VERSION ""

NS_ :

BS_:

BU_: DBG MASTER MOTOR SENSORS GEO BT

BO_ 95 HB_SENSORS: 1 SENSORS
 SG_ SENSOR_ALIVE : 0|1@1+ (1,0) [0|0] "HB-S" MASTER,MOTOR,GEO,BT

BO_ 96 HB_MOTORS: 1 MOTOR
 SG_ MOTOR_ALIVE : 0|1@1+ (1,0) [0|0] "HB-M" MASTER,SENSORS,GEO,BT

BO_ 97 HB_GEO: 1 GEO
 SG_ GEO_ALIVE : 0|1@1+ (1,0) [0|0] "HB-G" MASTER,SENSORS,MOTOR,BT

BO_ 98 HB_BT: 1 BT
 SG_ BT_ALIVE : 0|1@1+ (1,0) [0|0] "HB-BT" MASTER,SENSORS,MOTOR,GEO

BO_ 99 HB_MASTER: 1 MASTER
 SG_ MASTER_ALIVE : 0|1@1+ (1,0) [0|0] "HB-MT" BT,SENSORS,MOTOR,GEO

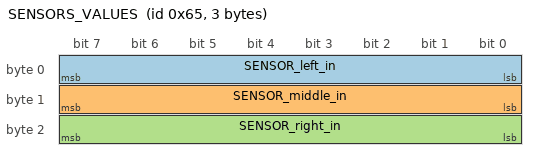
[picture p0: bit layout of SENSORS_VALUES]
BO_ 101 SENSORS_VALUES: 3 SENSORS
 SG_ SENSOR_left_in : 0|8@1+ (1,0) [0|0] "Inches" MASTER
 SG_ SENSOR_middle_in : 8|8@1+ (1,0) [0|0] "Inches" MASTER
 SG_ SENSOR_right_in : 16|8@1+ (1,0) [0|0] "Inches" MASTER

BO_ 203 MASTER_SPEED: 1 MASTER
 SG_ MASTER_Maintain_Speed : 0|8@1+ (1,0) [0|30] "mph" MOTOR

BO_ 204 MASTER_DIRECTION: 1 MASTER
 SG_ MASTER_Maintain_Direction : 0|8@1+ (1,0) [0|12] "" MOTOR
